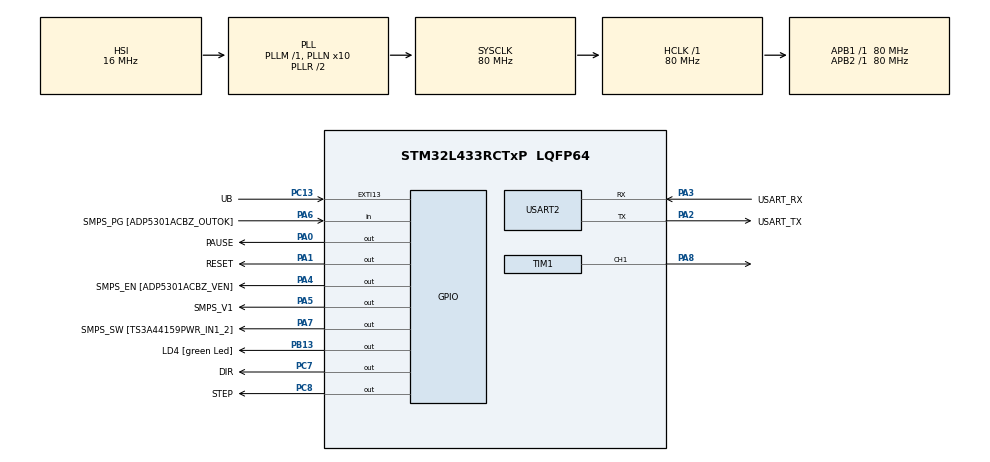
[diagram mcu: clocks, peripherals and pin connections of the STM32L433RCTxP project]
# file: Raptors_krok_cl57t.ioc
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Mcu.Family=STM32L4
Mcu.Name=STM32L433RCTxP
Mcu.Package=LQFP64
NVIC.EXTI15_10_IRQn=true\:0\:0\:false\:false\:true\:true\:true\:true
NVIC.PriorityGroup=NVIC_PRIORITYGROUP_4
NVIC.TIM2_IRQn=true\:0\:0\:false\:false\:true\:true\:true\:true
PA0.GPIO_Label=PAUSE
PA0.Signal=GPIO_Output
PA1.GPIO_Label=RESET
PA1.Signal=GPIO_Output
PA13\ (JTMS-SWDIO).GPIO_Label=TMS
PA13\ (JTMS-SWDIO).Mode=Serial_Wire
PA13\ (JTMS-SWDIO).Signal=SYS_JTMS-SWDIO
PA14\ (JTCK-SWCLK).GPIO_Label=TCK
PA14\ (JTCK-SWCLK).Mode=Serial_Wire
PA14\ (JTCK-SWCLK).Signal=SYS_JTCK-SWCLK
PA2.GPIO_Label=USART_TX
PA2.GPIO_Mode=GPIO_MODE_AF_PP
PA2.GPIO_PuPd=GPIO_NOPULL
PA2.GPIO_Speed=GPIO_SPEED_FREQ_VERY_HIGH
PA2.Mode=Asynchronous
PA2.Signal=USART2_TX
PA3.GPIO_Label=USART_RX
PA3.GPIO_Mode=GPIO_MODE_AF_PP
PA3.GPIO_PuPd=GPIO_NOPULL
PA3.GPIO_Speed=GPIO_SPEED_FREQ_VERY_HIGH
PA3.Mode=Asynchronous
PA3.Signal=USART2_RX
PA4.GPIO_Label=SMPS_EN [ADP5301ACBZ_VEN]
PA4.Signal=GPIO_Output
PA5.GPIO_Label=SMPS_V1
PA5.GPIO_ModeDefaultOutputPP=GPIO_MODE_OUTPUT_PP
PA5.GPIO_PuPd=GPIO_NOPULL
PA5.GPIO_Speed=GPIO_SPEED_FREQ_LOW
PA5.Signal=GPIO_Output
PA6.GPIO_Label=SMPS_PG [ADP5301ACBZ_OUTOK]
PA6.GPIO_PuPd=GPIO_PULLUP
PA6.Signal=GPIO_Input
PA7.GPIO_Label=SMPS_SW [TS3A44159PWR_IN1_2]
PA7.Signal=GPIO_Output
PA8.Signal=S_TIM1_CH1
PB13.GPIO_Label=LD4 [green Led]
PB13.Signal=GPIO_Output
PB3\ (JTDO-TRACESWO).GPIO_Label=SWO
PB3\ (JTDO-TRACESWO).Signal=SYS_JTDO-SWO
PC13.GPIO_Label=UB
PC13.Signal=GPXTI13
PC14-OSC32_IN\ (PC14).Mode=LSE-External-Oscillator
PC14-OSC32_IN\ (PC14).Signal=RCC_OSC32_IN
PC15-OSC32_OUT\ (PC15).Mode=LSE-External-Oscillator
PC15-OSC32_OUT\ (PC15).Signal=RCC_OSC32_OUT
PC7.GPIO_Label=DIR
PC7.Signal=GPIO_Output
PC8.GPIO_Label=STEP
PC8.Signal=GPIO_Output
PH0-OSC_IN\ (PH0).GPIO_Label=MCO
PH0-OSC_IN\ (PH0).Mode=HSE-External-Clock-Source
PH0-OSC_IN\ (PH0).Signal=RCC_OSC_IN
PH1-OSC_OUT\ (PH1).Signal=RCC_OSC_OUT
ProjectManager.HeapSize=0x200
ProjectManager.StackSize=0x400
ProjectManager.TargetToolchain=STM32CubeIDE
RCC.ADCFreq_Value=64000000
RCC.AHBFreq_Value=80000000
RCC.APB1Freq_Value=80000000
RCC.APB1TimFreq_Value=80000000
RCC.APB2Freq_Value=80000000
RCC.APB2TimFreq_Value=80000000
RCC.CortexFreq_Value=80000000
RCC.HCLKFreq_Value=80000000
RCC.HSE_VALUE=8000000
RCC.HSI48_VALUE=48000000
RCC.HSI_VALUE=16000000
RCC.MSI_VALUE=4000000
RCC.PLLN=10
RCC.PLLSourceVirtual=RCC_PLLSOURCE_HSI
RCC.PREFETCH_ENABLE=1
RCC.SYSCLKFreq_VALUE=80000000
RCC.SYSCLKSource=RCC_SYSCLKSOURCE_PLLCLK
RCC.USBFreq_Value=64000000
RCC.VCOOutputFreq_Value=160000000
SH.S_TIM1_CH1.0=TIM1_CH1,PWM Generation1 CH1
TIM1.Channel-PWM\ Generation1\ CH1=TIM_CHANNEL_1
TIM1.Period=9999
TIM1.Prescaler=31
TIM1.Pulse-PWM\ Generation1\ CH1=5000
TIM1.TIM_MasterOutputTrigger=TIM_TRGO_UPDATE
TIM1.TIM_MasterSlaveMode=TIM_MASTERSLAVEMODE_ENABLE
TIM2.Period=0
USART2.VirtualMode-Asynchronous=VM_ASYNC
VP_TIM1_VS_ClockSourceINT.Mode=Internal
VP_TIM2_VS_ClockSourceITR.Mode=TriggerSource_ITR0
VP_TIM2_VS_ControllerModeClock.Mode=Clock Mode
board=NUCLEO-L433RC-P

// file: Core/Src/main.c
/* USER CODE BEGIN Header */
/**
  ******************************************************************************
  * @file           : main.c
  * @brief          : Main program body
  ******************************************************************************
  * @attention
  *
  * Copyright (c) 2023 STMicroelectronics.
  * All rights reserved.
  *
  * This software is licensed under terms that can be found in the LICENSE file
  * in the root directory of this software component.
  * If no LICENSE file comes with this software, it is provided AS-IS.
  *
  ******************************************************************************
  */
/* USER CODE END Header */
#include "main.h"
#include "tim.h"
#include "usart.h"
#include "gpio.h"

/* USER CODE BEGIN Includes */
#include "stepper.h"
/* USER CODE END Includes */

void SystemClock_Config(void);

/* USER CODE BEGIN 0 */
volatile uint8_t sterowanie;
	void HAL_GPIO_EXTI_Callback(uint16_t GPIO_Pin)
	{
	  if (GPIO_Pin == UB_Pin) {
		  sterowanie++;
	  }
	}
/* USER CODE END 0 */

int main(void)
{

  /* MCU Configuration--------------------------------------------------------*/

  /* Reset of all peripherals, Initializes the Flash interface and the Systick. */
  HAL_Init();

  /* Configure the system clock */
  SystemClock_Config();

  /* Initialize all configured peripherals */
  MX_GPIO_Init();
  MX_USART2_UART_Init();
  MX_TIM1_Init();
  MX_TIM2_Init();
  /* USER CODE BEGIN 2 */
  stepper_init();

  /* USER CODE END 2 */

  /* Infinite loop */
  /* USER CODE BEGIN WHILE */
  while (1)
  {
	  if(sterowanie%2 ==0){
		  stepper_rot(360,60,STEPPER_CCW);
	  }
	  if(sterowanie%2 != 0 && sterowanie>1){
		  stepper_rot(360,60,STEPPER_CW);
	  }
    /* USER CODE END WHILE */

  }
}

void SystemClock_Config(void)
{
  RCC_OscInitTypeDef RCC_OscInitStruct = {0};
  RCC_ClkInitTypeDef RCC_ClkInitStruct = {0};

  /** Configure the main internal regulator output voltage
  */
  if (HAL_PWREx_ControlVoltageScaling(PWR_REGULATOR_VOLTAGE_SCALE1) != HAL_OK)
  {
    Error_Handler();
  }

  /** Initializes the RCC Oscillators according to the specified parameters
  * in the RCC_OscInitTypeDef structure.
  */
  RCC_OscInitStruct.OscillatorType = RCC_OSCILLATORTYPE_HSI;
  RCC_OscInitStruct.HSIState = RCC_HSI_ON;
  RCC_OscInitStruct.HSICalibrationValue = RCC_HSICALIBRATION_DEFAULT;
  RCC_OscInitStruct.PLL.PLLState = RCC_PLL_ON;
  RCC_OscInitStruct.PLL.PLLSource = RCC_PLLSOURCE_HSI;
  RCC_OscInitStruct.PLL.PLLM = 1;
  RCC_OscInitStruct.PLL.PLLN = 10;
  RCC_OscInitStruct.PLL.PLLP = RCC_PLLP_DIV7;
  RCC_OscInitStruct.PLL.PLLQ = RCC_PLLQ_DIV2;
  RCC_OscInitStruct.PLL.PLLR = RCC_PLLR_DIV2;
  if (HAL_RCC_OscConfig(&RCC_OscInitStruct) != HAL_OK)
  {
    Error_Handler();
  }

  /** Initializes the CPU, AHB and APB buses clocks
  */
  RCC_ClkInitStruct.ClockType = RCC_CLOCKTYPE_HCLK|RCC_CLOCKTYPE_SYSCLK
                              |RCC_CLOCKTYPE_PCLK1|RCC_CLOCKTYPE_PCLK2;
  RCC_ClkInitStruct.SYSCLKSource = RCC_SYSCLKSOURCE_PLLCLK;
  RCC_ClkInitStruct.AHBCLKDivider = RCC_SYSCLK_DIV1;
  RCC_ClkInitStruct.APB1CLKDivider = RCC_HCLK_DIV1;
  RCC_ClkInitStruct.APB2CLKDivider = RCC_HCLK_DIV1;

  if (HAL_RCC_ClockConfig(&RCC_ClkInitStruct, FLASH_LATENCY_4) != HAL_OK)
  {
    Error_Handler();
  }
}

/* USER CODE BEGIN 4 */
void HAL_TIM_PeriodElapsedCallback(TIM_HandleTypeDef *htim){
	if(htim->Instance == TIM2){
		stepper_stop();
	}
}
/* USER CODE END 4 */

void Error_Handler(void)
{
  __disable_irq();
  while (1)
  {
  }
}
